# secure_dma: IP-XACT component
VLNV tenstorrent.com:ocah:secure_dma:1.0

## Address spaces and blocks
secure_dma_mmap.secure_dma: base 'h0, range 'h150, width 32

## Registers
Registers are 32-bit, read-write, reset 0x0 unless marked. A register's access mark holds for its fields unless they carry their own. Offsets are from the block's base; lines under a group give offsets from that group; [hi:lo] are bit positions; {n}, {i} and the like mark numbered series; 'fields as' and 'values as' point back to an identical list; <NAME> marks a mode.

## secure_dma_mmap.secure_dma — DMA Controller for the integrated OpenTitan.
Base 0x00000000
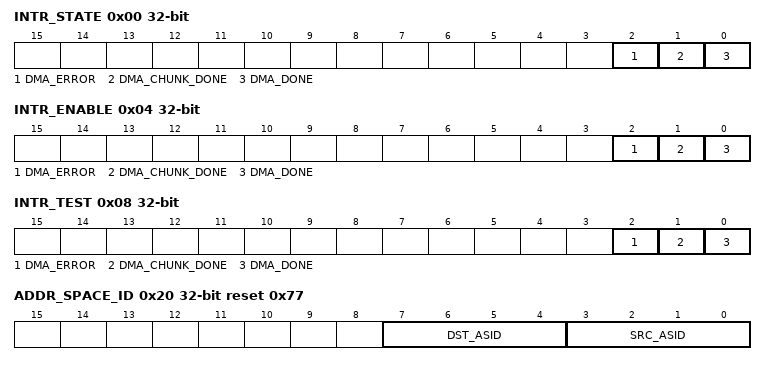
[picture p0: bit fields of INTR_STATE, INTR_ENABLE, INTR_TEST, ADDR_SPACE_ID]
0x00 INTR_STATE ro
  [2] DMA_ERROR — DMA error has occurred. DMA_STATUS.error_code register shows the details.
  [1] DMA_CHUNK_DONE — Indicates the transfer of a single chunk has been completed.
  [0] DMA_DONE — DMA operation has been completed.
0x04 INTR_ENABLE
  [2] DMA_ERROR — Enable interrupt when !!INTR_STATE.dma_error is set.
  [1] DMA_CHUNK_DONE — Enable interrupt when !!INTR_STATE.dma_chunk_done is set.
  [0] DMA_DONE — Enable interrupt when !!INTR_STATE.dma_done is set.
0x08 INTR_TEST wo
  [2] DMA_ERROR — Write 1 to force !!INTR_STATE.dma_error to 1.
  [1] DMA_CHUNK_DONE — Write 1 to force !!INTR_STATE.dma_chunk_done to 1.
  [0] DMA_DONE — Write 1 to force !!INTR_STATE.dma_done to 1.
0x0C ALERT_TEST wo
  [0] FATAL_FAULT — Write 1 to trigger one alert event of this kind.
0x10 SRC_ADDR_LO
  [31:0] SRC_ADDR_LO — Lower 32 bits of the source address. Must be aligned to the transfer width.
0x14 SRC_ADDR_HI
  [31:0] SRC_ADDR_HI — Upper 32 bits of the physical or virtual address of memory location within SoC memory address map or physical address within OT non-secure memory space. Must be aligned to the transfer width. Source and destination address must have the same alignment.
0x18 DST_ADDR_LO
  [31:0] DST_ADDR_LO — Lower 32 bits of the destination address. Must be aligned to the transfer width. Source and destination address must have the same alignment.
0x1C DST_ADDR_HI
  [31:0] DST_ADDR_HI — Upper 32 bits of the physical or virtual address of memory location within SoC memory address map or physical address within OT non-secure memory space. Must be aligned to the transfer width. Source and destination address must have the same alignment.
0x20 ADDR_SPACE_ID reset 0x77
  [7:4] DST_ASID — Target address space that the destination address pointer refers to.
  [3:0] SRC_ASID — Target address space that the source address pointer refers to.
0x24 ENABLED_MEMORY_RANGE_BASE
  [31:0] BASE — Base Address to mark the start of the DMA enabled memory range within the OT internal memory space.
0x28 ENABLED_MEMORY_RANGE_LIMIT
  [31:0] LIMIT — Limit Address to mark the end of the DMA enabled memory range within the OT internal memory space; inclusive.
0x2C RANGE_VALID
  [0] RANGE_VALID — Once set the enabled memory base and limit registers are valid.
0x30 RANGE_REGWEN reset 0x6
  [3:0] REGWEN write-0-clears — Used by firmware to lock the DMA enabled memory range configuration registers from further modification. Once this register is set to kMultiBitBool4False, it can only be set to kMultiBitBool4True through a reset event. Default Value = kMultiBitBool4True -> Unlocked at reset.
    6=True; 9=False
0x34 CFG_REGWEN ro reset 0x6
  [3:0] REGWEN — Used by hardware to lock the DMA configuration registers. This register is purely managed by hardware and only software readable.
    6=True; 9=False
0x38 TOTAL_DATA_SIZE
  [31:0] DATA_SIZE — Total size (in bytes) of the data to be transferred. The complete transfer operation may consist of multiple chunks of data as specified by the CHUNK_DATA_SIZE register. Minimum: 1 byte. Maximum: May be restricted to a maximum pre-defined size based on OT DMA enabled memory space allocation. Works in conjunction with the TRANSFER_WIDTH register.
0x3C CHUNK_DATA_SIZE
  [31:0] DATA_SIZE — Size (in bytes) for a single DMA transfer. In hardware handshake mode, the DMA reads in chunks of CHUNK_DATA_SIZE from the peripheral. For a single memory transfer CHUNK_DATA_SIZE and TOTAL_DATA_SIZE are set to the same value. Minimum: 1 byte. Maximum: May be restricted to a maximum pre-defined size based on OT DMA enabled memory space allocation. Works in conjunction with the TRANSFER_WIDTH register.
0x40 TRANSFER_WIDTH reset 0x2
  [1:0] TRANSACTION_WIDTH — Denotes the width of each transaction that the DMA shall issue during the data movement. Multiple transactions of this width will be issued until TOTAL_DATA_SIZE bytes have been transferred. Note that firmware may need to set a different value if a receiving IP supports a read / write transaction width that is less than 1 DWORD. This does not affect the wrap-around mechanism. Note that the value 3 for this register represents an invalid configuration that leads to an error.
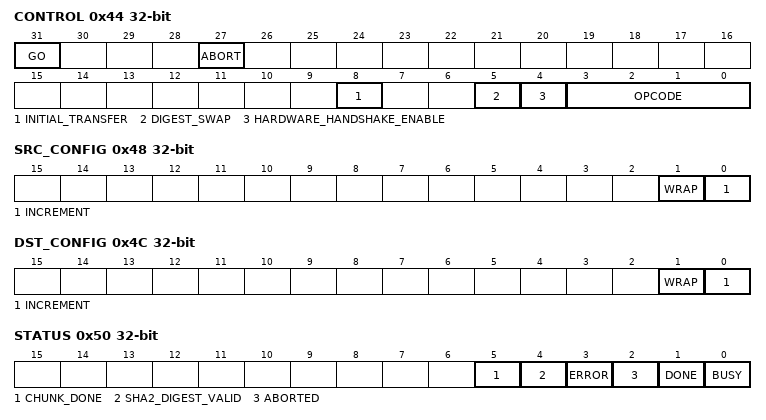
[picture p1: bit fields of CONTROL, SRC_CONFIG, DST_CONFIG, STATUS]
0x44 CONTROL access per field
  [31] GO rw — Setting this bit triggers the DMA operation. For normal operation, the DMA engine clears the `go` bit automatically after the configured operation is complete. For hardware handshake operation, the DMA engine keeps the `go` bit set across chunks and clears it, setting `status.done`, once `total_data_size` bytes have been transferred. Firmware clears the `go` bit to stop the hardware handshake operation earlier.
  [27] ABORT wo — Aborts the DMA operation if this bit is set. Sets the corresponding bit in the status register once abort operation is complete. Any OpenTitan-internal transactions are guaranteed to complete, but there are no guarantees on the SoC interface.
  [8] INITIAL_TRANSFER rw — Marks the initial transfer to initialize the DMA and SHA engine for one transfer that can span over multiple single DMA transfers. Used for hardware handshake and ordinary transfers, in which multiple transfers contribute to a final digest. Note, for non-handshake transfers with inline hashing mode enabled, this bit must be set to also mark the first transfer.
  [5] DIGEST_SWAP rw — Digest register byte swap. If 1 the value in each digest output register is converted to big-endian byte order. This setting does not affect the order of the digest output registers, !!SHA2_DIGEST_0 still contains the first 4 bytes of the digest.
  [4] HARDWARE_HANDSHAKE_ENABLE rw — Enable hardware handshake mode. Used to clear FIFOs from low speed IO peripherals receiving data, e.g., I3C receive buffer. Listen to an input trigger signal. Read data from source address location. Copy to destination address. Number of bytes specified in size register. Note assumption is the peripheral lowers input once FIFO is cleared. No explicit clearing necessary.
  [3:0] OPCODE rw — Defines the type of DMA operations.
0x48 SRC_CONFIG
  [1] WRAP — When 0: Chunks occupy contiguous ascending addresses. When 1: Source address wraps back to the starting address when finishing a chunk.
  [0] INCREMENT — Defines the increment behavior after every DMA read. When 0: Source address is not changed. All reads are done from the same address. When 1: Source address is incremented by transfer_width after each read.
0x4C DST_CONFIG
  [1] WRAP — When 0: Chunks occupy contiguous ascending addresses. When 1: Destination address wraps back to the starting address when finishing a chunk.
  [0] INCREMENT — Defines the increment behavior after every DMA write. When 0: Destination address is not changed. All writes are done to the same address. When 1: Destination address is incremented by transfer_width after each write.
0x50 STATUS access per field
  [5] CHUNK_DONE rw write-1-clears — Transfer of a single chunk is complete. Only raised for multi-chunk memory-to-memory transfers. Cleared automatically by the hardware when starting the transfer of a new chunk.
  [4] SHA2_DIGEST_VALID ro — Indicates whether the SHA2_DIGEST register contains a valid digest. This value is cleared on the initial transfer and set when the digest is written.
  [3] ERROR rw write-1-clears — Error occurred during the operation. ERROR_CODE register denotes the source of the error.
  [2] ABORTED rw write-1-clears — Set once aborted operation drains.
  [1] DONE rw write-1-clears — Configured DMA operation is complete. Cleared automatically by the hardware when starting a new transfer.
  [0] BUSY ro — DMA operation is active if this bit is set. DMA engine clears this bit when operation is complete. This bit may be set as long as hardware handshake mode is active and triggered.
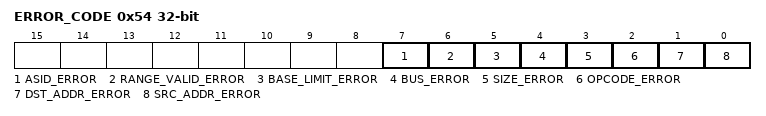
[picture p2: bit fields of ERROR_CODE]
0x54 ERROR_CODE ro
  [7] ASID_ERROR — The source or destination ASID contains an invalid value.
  [6] RANGE_VALID_ERROR — The DMA enabled memory range is not configured.
  [5] BASE_LIMIT_ERROR — The base and limit addresses contain an invalid value.
  [4] BUS_ERROR — The bus transfer returned an error.
  [3] SIZE_ERROR — TRANSFER_WIDTH encodes an invalid value, TOTAL_DATA_SIZE or CHUNK_SIZE are zero, or inline hashing is not using 32-bit transfer width
  [2] OPCODE_ERROR — Opcode is invalid.
  [1] DST_ADDR_ERROR — Destination address is invalid.
  [0] SRC_ADDR_ERROR — Source address is invalid.
{0x58+4i} SHA2_DIGEST_0[{i}] (i=0..15) ro
  [31:0] DATA_0 — SHA2 digest data
0x98 HANDSHAKE_INTR_ENABLE reset 0x7FF
  [10:0] MASK — Enable bits for incoming handshake interrupt wires.
0x9C CLEAR_INTR_SRC
  [10:0] SOURCE — Source N needs interrupt cleared
0xA0 CLEAR_INTR_BUS
  [10:0] BUS — Bus selection bit for source N.
{0xA4+4i} INTR_SRC_ADDR_0[{i}] (i=0..10)
  [31:0] ADDR_0 — Destination address for interrupt source clearing write.
{0x124+4i} INTR_SRC_WR_VAL_0[{i}] (i=0..10)
  [31:0] WR_VAL_0 — Write value for interrupt clearing write.

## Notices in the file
SPDX-License-Identifier: Apache-2.0
SPDX-FileCopyrightText: 2026 Tenstorrent USA, Inc.
